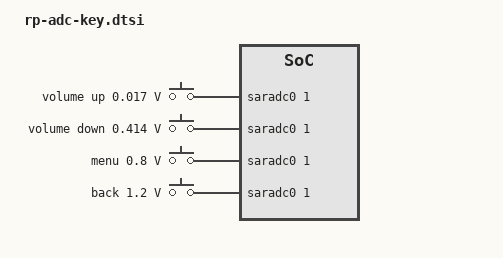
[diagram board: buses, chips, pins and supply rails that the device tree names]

/ {
	adc_keys: adc-keys {
		compatible = "adc-keys";
		io-channels = <&saradc0 1>;
		io-channel-names = "buttons";
		keyup-threshold-microvolt = <1800000>;
		poll-interval = <100>;

		vol-up-key {
			linux,code = <KEY_VOLUMEUP>;
			label = "volume up";
			press-threshold-microvolt = <17000>;
		};

		vol-down-key {
			linux,code = <KEY_VOLUMEDOWN>;
			label = "volume down";
			press-threshold-microvolt = <414000>;
		};

		menu-key {
			linux,code = <KEY_MENU>;
			label = "menu";
			press-threshold-microvolt = <800000>;
		};

		back-key {
			linux,code = <KEY_BACK>;
			label = "back";
			press-threshold-microvolt = <1200000>;
		};
	};
};
